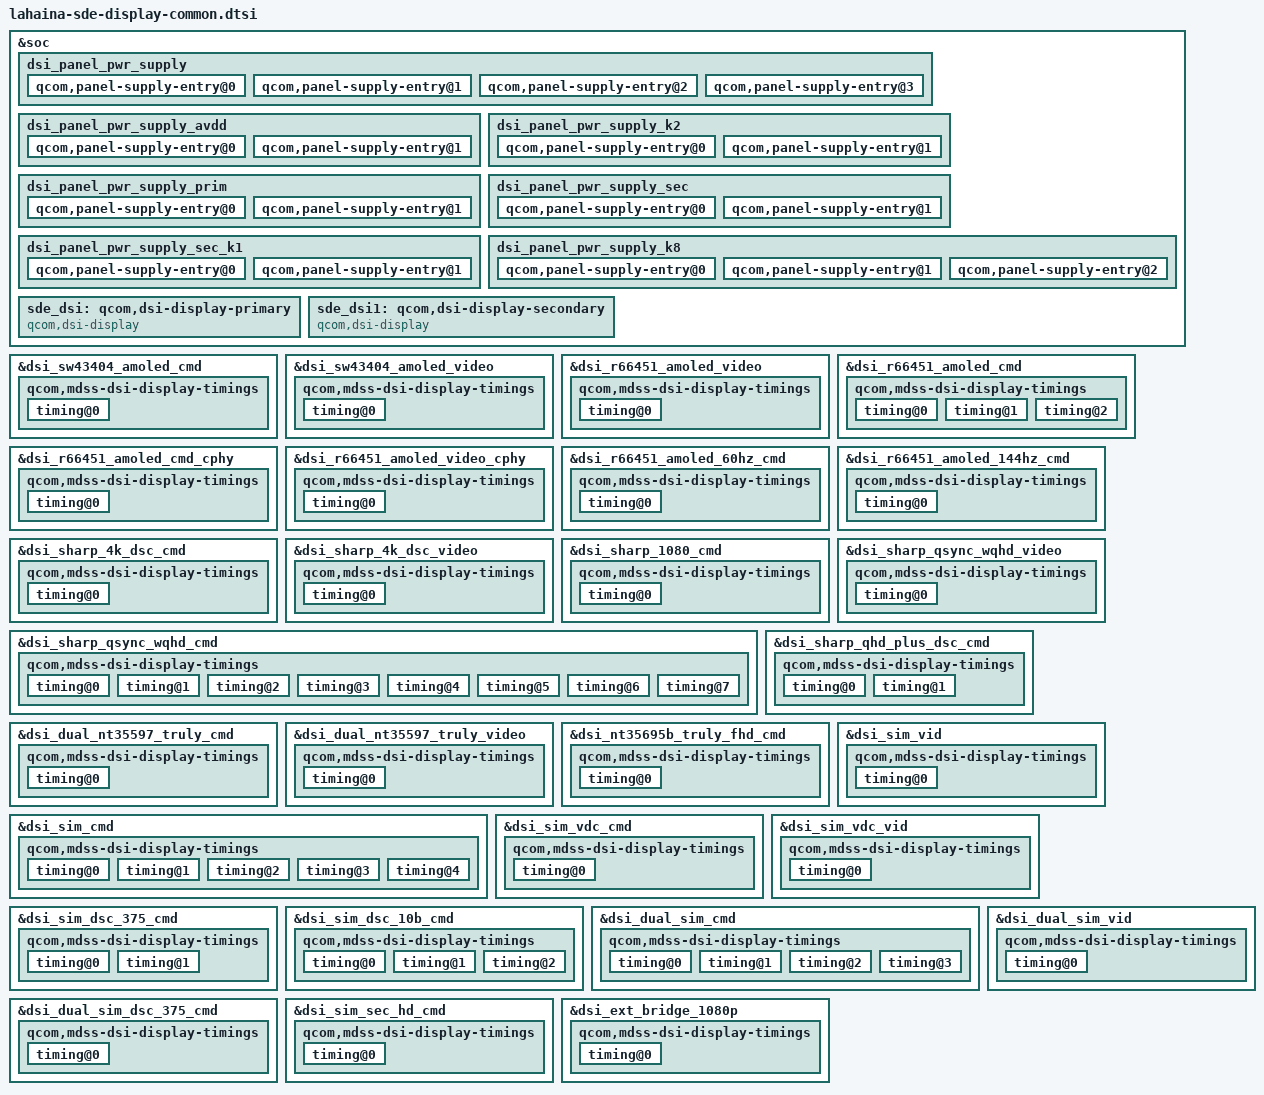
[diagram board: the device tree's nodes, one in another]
#include "dsi-panel-sw43404-amoled-dsc-wqhd-cmd.dtsi"
#include "dsi-panel-sw43404-amoled-dsc-wqhd-video.dtsi"
#include "dsi-panel-sw43404-amoled-dsc-fhd-plus-cmd.dtsi"
#include "dsi-panel-sharp-dsc-4k-cmd.dtsi"
#include "dsi-panel-sharp-dsc-4k-video.dtsi"
#include "dsi-panel-sharp-dsc-qhd-plus-cmd.dtsi"
#include "dsi-panel-sharp-qsync-wqhd-cmd.dtsi"
#include "dsi-panel-sharp-qsync-wqhd-video.dtsi"
#include "dsi-panel-sharp-1080p-cmd.dtsi"
#include "dsi-panel-nt35597-truly-dualmipi-wqxga-cmd.dtsi"
#include "dsi-panel-nt35597-truly-dualmipi-wqxga-video.dtsi"
#include "dsi-panel-nt35695b-truly-fhd-cmd.dtsi"
#include "dsi-panel-nt35695b-truly-fhd-video.dtsi"
#include "dsi-panel-r66451-dsc-fhd-plus-video-cphy.dtsi"
#include "dsi-panel-r66451-dsc-fhd-plus-cmd-cphy.dtsi"
#include "dsi-panel-r66451-dsc-fhd-plus-video.dtsi"
#include "dsi-panel-r66451-dsc-fhd-plus-cmd.dtsi"
#include "dsi-panel-r66451-dsc-fhd-plus-60hz-cmd.dtsi"
#include "dsi-panel-r66451-dsc-fhd-plus-144hz-cmd.dtsi"
#include "dsi-panel-ext-bridge-1080p.dtsi"
#include "dsi-panel-sim-cmd.dtsi"
#include "dsi-panel-sim-video.dtsi"
#include "dsi-panel-sim-dsc375-cmd.dtsi"
#include "dsi-panel-sim-dsc-10bit-cmd.dtsi"
#include "dsi-panel-sim-dualmipi-cmd.dtsi"
#include "dsi-panel-sim-dualmipi-video.dtsi"
#include "dsi-panel-sim-dualmipi-dsc375-cmd.dtsi"
#include "dsi-panel-sim-sec-hd-cmd.dtsi"
#include <dt-bindings/clock/mdss-5nm-pll-clk.h>
#include "dsi-panel-sim-vdc-vid.dtsi"
#include "dsi-panel-sim-vdc-cmd.dtsi"
#include "dsi-panel-k2-38-08-0a-dsc-cmd.dtsi"
#include "dsi-panel-k2-38-08-0a-mp-dsc-cmd.dtsi"
#include "dsi-panel-k2b-38-08-0a-dsc-cmd.dtsi"
#include "dsi-panel-j18-42-06-0a-prim-dsc-cmd.dtsi"
#include "dsi-panel-j18-42-06-0a-sec-dsc-cmd.dtsi"
#include "dsi-panel-k11-38-08-0a-dsc-cmd.dtsi"
#include "dsi-panel-prim-sim-video.dtsi"
#include "dsi-panel-sec-sim-video.dtsi"
#include "dsi-panel-k1-43-06-00-sec-cmd.dtsi"
#include "dsi-panel-k1-43-06-00-sec-video.dtsi"
#include "dsi-panel-k8-42-02-0a-dsc-cmd.dtsi"

&soc {
	dsi_panel_pwr_supply: dsi_panel_pwr_supply {
		#address-cells = <1>;
		#size-cells = <0>;

		qcom,panel-supply-entry@0 {
			reg = <0>;
			qcom,supply-name = "vddio";
			qcom,supply-min-voltage = <1800000>;
			qcom,supply-max-voltage = <1800000>;
			qcom,supply-enable-load = <60700>;
			qcom,supply-disable-load = <80>;
			qcom,supply-post-on-sleep = <20>;
		};

		qcom,panel-supply-entry@1 {
			reg = <1>;
			qcom,supply-name = "vdd";
			qcom,supply-min-voltage = <3000000>;
			qcom,supply-max-voltage = <3000000>;
			qcom,supply-enable-load = <10000>;
			qcom,supply-disable-load = <0>;
			qcom,supply-post-on-sleep = <0>;
		};

		qcom,panel-supply-entry@2 {
			reg = <2>;
			qcom,supply-name = "lab";
			qcom,supply-min-voltage = <4600000>;
			qcom,supply-max-voltage = <6000000>;
			qcom,supply-enable-load = <0>;
			qcom,supply-disable-load = <0>;
		};

		qcom,panel-supply-entry@3 {
			reg = <3>;
			qcom,supply-name = "ibb";
			qcom,supply-min-voltage = <4600000>;
			qcom,supply-max-voltage = <6000000>;
			qcom,supply-enable-load = <0>;
			qcom,supply-disable-load = <0>;
			qcom,supply-post-on-sleep = <20>;
		};
	};

	dsi_panel_pwr_supply_avdd: dsi_panel_pwr_supply_avdd {
		#address-cells = <1>;
		#size-cells = <0>;

		qcom,panel-supply-entry@0 {
			reg = <0>;
			qcom,supply-name = "vddio";
			qcom,supply-min-voltage = <1800000>;
			qcom,supply-max-voltage = <1800000>;
			qcom,supply-enable-load = <182000>;
			qcom,supply-disable-load = <80>;
			qcom,supply-post-on-sleep = <20>;
		};

		qcom,panel-supply-entry@1 {
			reg = <1>;
			qcom,supply-name = "avdd";
			qcom,supply-min-voltage = <4600000>;
			qcom,supply-max-voltage = <6000000>;
			qcom,supply-enable-load = <100000>;
			qcom,supply-disable-load = <100>;
		};
	};

	dsi_panel_pwr_supply_k2: dsi_panel_pwr_supply_k2 {
		#address-cells = <1>;
		#size-cells = <0>;

		qcom,panel-supply-entry@0 {
			reg = <0>;
			qcom,supply-name = "vddio";
			qcom,supply-min-voltage = <1800000>;
			qcom,supply-max-voltage = <1800000>;
			qcom,supply-enable-load = <60700>;
			qcom,supply-disable-load = <80>;
		};

		qcom,panel-supply-entry@1 {
			reg = <1>;
			qcom,supply-name = "vdd";
			qcom,supply-min-voltage = <3000000>;
			qcom,supply-max-voltage = <3000000>;
			qcom,supply-enable-load = <10000>;
			qcom,supply-disable-load = <0>;
			qcom,supply-pre-off-sleep = <10>;
		};
	};

	dsi_panel_pwr_supply_prim: dsi_panel_pwr_supply_prim {
	#address-cells = <1>;
	#size-cells = <0>;

		qcom,panel-supply-entry@0 {
			reg = <0>;
			qcom,supply-name = "vddio";
			qcom,supply-min-voltage = <1900000>;
			qcom,supply-max-voltage = <1900000>;
			qcom,supply-enable-load = <62000>;
			qcom,supply-disable-load = <80>;
			qcom,supply-pre-on-sleep = <0>;
			qcom,supply-pre-off-sleep = <3>;
			qcom,supply-post-on-sleep = <3>;
			qcom,supply-post-off-sleep = <0>;
		};

		qcom,panel-supply-entry@1 {
			reg = <1>;
			qcom,supply-name = "vdd";
			qcom,supply-min-voltage = <3000000>;
			qcom,supply-max-voltage = <3000000>;
			qcom,supply-enable-load = <100000>;
			qcom,supply-disable-load = <100>;
			qcom,supply-pre-on-sleep = <0>;
			qcom,supply-pre-off-sleep = <2>;
			qcom,supply-post-on-sleep = <10>;
			qcom,supply-post-off-sleep = <0>;
		};
	};

	dsi_panel_pwr_supply_sec: dsi_panel_pwr_supply_sec {
	#address-cells = <1>;
	#size-cells = <0>;

		qcom,panel-supply-entry@0 {
			reg = <0>;
			qcom,supply-name = "sec-vddio";
			qcom,supply-min-voltage = <1800000>;
			qcom,supply-max-voltage = <1800000>;
			qcom,supply-enable-load = <62000>;
			qcom,supply-disable-load = <80>;
			qcom,supply-pre-on-sleep = <0>;
			qcom,supply-pre-off-sleep = <2>;
			qcom,supply-post-on-sleep = <3>;
			qcom,supply-post-off-sleep = <0>;
		};

		qcom,panel-supply-entry@1 {
			reg = <1>;
			qcom,supply-name = "sec-vdd";
			qcom,supply-min-voltage = <3000000>;
			qcom,supply-max-voltage = <3000000>;
			qcom,supply-enable-load = <100000>;
			qcom,supply-disable-load = <100>;
			qcom,supply-pre-on-sleep = <0>;
			qcom,supply-pre-off-sleep = <1>;
			qcom,supply-post-on-sleep = <10>;
			qcom,supply-post-off-sleep = <0>;
		};
	};

	dsi_panel_pwr_supply_sec_k1: dsi_panel_pwr_supply_sec_k1 {
	#address-cells = <1>;
	#size-cells = <0>;

		qcom,panel-supply-entry@0 {
			reg = <0>;
			qcom,supply-name = "sec-vddio";
			qcom,supply-min-voltage = <1800000>;
			qcom,supply-max-voltage = <1800000>;
			qcom,supply-enable-load = <62000>;
			qcom,supply-disable-load = <80>;
			qcom,supply-pre-on-sleep = <0>;
			qcom,supply-pre-off-sleep = <2>;
			qcom,supply-post-on-sleep = <3>;
			qcom,supply-post-off-sleep = <0>;
		};

		qcom,panel-supply-entry@1 {
			reg = <1>;
			qcom,supply-name = "sec-vdd";
			qcom,supply-min-voltage = <3000000>;
			qcom,supply-max-voltage = <3000000>;
			qcom,supply-enable-load = <100000>;
			qcom,supply-disable-load = <100>;
			qcom,supply-pre-on-sleep = <0>;
			qcom,supply-pre-off-sleep = <1>;
			qcom,supply-post-on-sleep = <10>;
			qcom,supply-post-off-sleep = <0>;
		};
	};

	dsi_panel_pwr_supply_k8: dsi_panel_pwr_supply_k8 {
		#address-cells = <1>;
		#size-cells = <0>;

		qcom,panel-supply-entry@0 {
			reg = <0>;
			qcom,supply-name = "vddio";
			qcom,supply-min-voltage = <1800000>;
			qcom,supply-max-voltage = <1800000>;
			qcom,supply-enable-load = <60700>;
			qcom,supply-disable-load = <80>;
			qcom,supply-pre-off-sleep = <2>;
			qcom,supply-post-on-sleep = <2>;
		};

		qcom,panel-supply-entry@1 {
			reg = <1>;
			qcom,supply-name = "vddd";
			qcom,supply-min-voltage = <1800000>;
			qcom,supply-max-voltage = <1800000>;
			qcom,supply-enable-load = <60700>;
			qcom,supply-disable-load = <80>;
			qcom,supply-pre-off-sleep = <2>;
			qcom,supply-post-on-sleep = <2>;
		};

		qcom,panel-supply-entry@2 {
			reg = <2>;
			qcom,supply-name = "avdd";
			qcom,supply-min-voltage = <3000000>;
			qcom,supply-max-voltage = <3000000>;
			qcom,supply-enable-load = <10000>;
			qcom,supply-disable-load = <0>;
			qcom,supply-pre-off-sleep = <2>;
			qcom,supply-post-on-sleep = <2>;
		};
	};

	sde_dsi: qcom,dsi-display-primary {
		compatible = "qcom,dsi-display";
		label = "primary";

		qcom,dsi-ctrl = <&mdss_dsi0 &mdss_dsi1>;
		qcom,dsi-phy = <&mdss_dsi_phy0 &mdss_dsi_phy1>;

		qcom,mdp = <&mdss_mdp>;
		qcom,dsi-default-panel = <&dsi_sw43404_amoled_cmd>;
		qcom,demura-panel-id = <0x0 0x0>;
	};

	sde_dsi1: qcom,dsi-display-secondary {
		compatible = "qcom,dsi-display";
		label = "secondary";

		qcom,dsi-ctrl = <&mdss_dsi0 &mdss_dsi1>;
		qcom,dsi-phy = <&mdss_dsi_phy0 &mdss_dsi_phy1>;
		qcom,mdp = <&mdss_mdp>;
		qcom,demura-panel-id = <0x0 0x0>;
	};
};

/* PHY TIMINGS REVISION YC with reduced margins*/
&dsi_sw43404_amoled_cmd {
	qcom,dsi-select-clocks = "mux_byte_clk0", "mux_pixel_clk0";
	qcom,dsi-dyn-clk-enable;
	qcom,dsi-dyn-clk-list = <606979440 604450359 601921278>;

	qcom,mdss-dsi-panel-status-check-mode = "reg_read";
	qcom,mdss-dsi-panel-status-command = [06 01 00 01 00 00 01 0a];
	qcom,mdss-dsi-panel-status-command-state = "dsi_lp_mode";
	qcom,mdss-dsi-panel-status-value = <0x9c>;
	qcom,mdss-dsi-panel-status-read-length = <1>;
	qcom,esd-check-enabled;

	qcom,dsi-panel-gpio-address = <0x0F100000 0x1000>;
	qcom,dsi-panel-gpio-pins = <12 24 82>;
	qcom,dsi-panel-gpio-names = "reg-gpio", "reset-gpio", "platform-te-gpio";

	qcom,mdss-dsi-display-timings {
		timing@0 {
			qcom,mdss-dsi-panel-phy-timings = [00 14 05 05 13 13 05
				05 06 02 04 00 12 0a];
			qcom,display-topology = <2 2 1>;
			qcom,default-topology-index = <0>;

			qcom,panel-roi-alignment = <720 180 180 180 1440 180>;
		};
	};
};

&dsi_sw43404_amoled_video {
	qcom,mdss-dsi-qsync-min-refresh-rate = <55>;
	qcom,dsi-select-clocks = "mux_byte_clk0", "mux_pixel_clk0",
			"src_byte_clk0", "src_pixel_clk0",
			"shadow_byte_clk0", "shadow_pixel_clk0";
	qcom,dsi-dyn-clk-enable;
	qcom,dsi-dyn-clk-list = <534712320 532484352 530256384>;
	qcom,dsi-dyn-clk-type = "constant-fps-adjust-hfp";

	qcom,mdss-dsi-panel-status-check-mode = "reg_read";
	qcom,mdss-dsi-panel-status-command = [06 01 00 01 00 00 01 0a];
	qcom,mdss-dsi-panel-status-command-state = "dsi_lp_mode";
	qcom,mdss-dsi-panel-status-value = <0x9c>;
	qcom,mdss-dsi-panel-status-read-length = <1>;
	qcom,esd-check-enabled;

	qcom,dsi-panel-gpio-address = <0x0F100000 0x1000>;
	qcom,dsi-panel-gpio-pins = <12 24>;
	qcom,dsi-panel-gpio-names = "reg-gpio", "reset-gpio";

	qcom,mdss-dsi-display-timings {
		timing@0 {
			qcom,mdss-dsi-panel-phy-timings = [00 14 05 05 13 1e 05
				05 06 02 04 00 12 0a];
			qcom,display-topology = <2 2 1>;
			qcom,default-topology-index = <0>;
		};
	};
};

&dsi_r66451_amoled_video {
	qcom,dsi-select-clocks = "mux_byte_clk0", "mux_pixel_clk0";
	qcom,dsi-supported-dfps-list = <120 90 60>;
	qcom,mdss-dsi-pan-enable-dynamic-fps;
	qcom,mdss-dsi-min-refresh-rate = <60>;
	qcom,mdss-dsi-max-refresh-rate = <120>;
	qcom,mdss-dsi-pan-fps-update = "dfps_immediate_porch_mode_vfp";

	qcom,dsi-panel-gpio-address = <0x0F100000 0x1000>;
	qcom,dsi-panel-gpio-pins = <12 24>;
	qcom,dsi-panel-gpio-names = "reg-gpio", "reset-gpio";

	qcom,mdss-dsi-display-timings {
		timing@0 {
			qcom,mdss-dsi-panel-phy-timings = [00 1b 08 07 0d 0b 08
				08 05 02 04 00 17 0c];
			qcom,display-topology = <2 2 1>;
			qcom,default-topology-index = <0>;
		};
	};
};

&dsi_r66451_amoled_cmd {
	qcom,dsi-select-clocks = "mux_byte_clk0", "mux_pixel_clk0";
	qcom,dsi-select-sec-clocks = "mux_byte_clk1", "mux_pixel_clk1";

	qcom,dsi-panel-gpio-address = <0x0F100000 0x1000>;
	qcom,dsi-panel-gpio-pins = <12 24 82>;
	qcom,dsi-panel-gpio-names = "reg-gpio", "reset-gpio", "platform-te-gpio";

	qcom,mdss-dsi-panel-status-check-mode = "reg_read";
	qcom,mdss-dsi-panel-status-command = [06 01 00 01 00 00 01 0a];
	qcom,mdss-dsi-panel-status-command-state = "dsi_lp_mode";
	qcom,mdss-dsi-panel-status-value = <0x1c>;
	qcom,mdss-dsi-panel-status-read-length = <1>;
	qcom,esd-check-enabled;

	qcom,mdss-dsi-display-timings {
		timing@0 {
			qcom,mdss-dsi-panel-phy-timings = [00 10 04 04 12 1e 04
				04 03 02 04 00 0e 09];
			qcom,display-topology = <2 2 1>;
			qcom,default-topology-index = <0>;
		};

		timing@1 {
			qcom,mdss-dsi-panel-phy-timings = [00 16 06 05 14 1f 06
				06 06 02 04 00 14 0a];
			qcom,display-topology = <2 2 1>;
			qcom,default-topology-index = <0>;
		};

		timing@2 {
			qcom,mdss-dsi-panel-phy-timings = [00 1c 08 07 17 16 07
				07 08 02 04 00 19 0c];
			qcom,display-topology = <2 2 1>;
			qcom,default-topology-index = <0>;
		};
	};
};

&dsi_r66451_amoled_cmd_cphy {
	qcom,dsi-select-clocks = "mux_byte_clk0", "mux_pixel_clk0",
			"cphy_byte_clk0", "cphy_pixel_clk0";
	qcom,dsi-dyn-clk-enable;
	qcom,dsi-dyn-clk-list = <195173804 194360579 193547355>;
	qcom,mdss-dsi-display-timings {
		timing@0 {
			qcom,mdss-dsi-panel-phy-timings = [00 00 00 00 1e 17 04
				19 03 02 04 00 00 00];
			qcom,display-topology = <2 2 1>;
			qcom,default-topology-index = <0>;
		};
	};
};

&dsi_r66451_amoled_video_cphy {
	qcom,dsi-select-clocks = "mux_byte_clk0", "mux_pixel_clk0",
			"cphy_byte_clk0", "cphy_pixel_clk0",
			"shadow_cphybyte_clk0", "shadow_cphypixel_clk0";
	qcom,dsi-dyn-clk-enable;
	qcom,dsi-dyn-clk-list = <394178400 392535990 387608760>;
	qcom,dsi-dyn-clk-type = "constant-fps-adjust-hfp";
	qcom,mdss-dsi-display-timings {
		timing@0 {
			qcom,mdss-dsi-panel-phy-timings = [00 00 00 00 1e 17 04
				19 03 02 04 00 00 00];
			qcom,display-topology = <2 2 1>;
			qcom,default-topology-index = <0>;
		};
	};
};

&dsi_r66451_amoled_60hz_cmd {
	qcom,dsi-select-clocks = "mux_byte_clk0", "mux_pixel_clk0";

	qcom,dsi-dyn-clk-enable;
	qcom,dsi-dyn-clk-list = <327096544 325733641 324370739>;

	qcom,esd-check-enabled;
	qcom,mdss-dsi-panel-status-check-mode = "reg_read";
	qcom,mdss-dsi-panel-status-command = [06 01 00 01 00 00 01 0a];
	qcom,mdss-dsi-panel-status-command-state = "dsi_lp_mode";
	qcom,mdss-dsi-panel-status-value = <0x1c>;
	qcom,mdss-dsi-panel-status-read-length = <1>;

	qcom,mdss-dsi-display-timings {
		timing@0 {
			qcom,mdss-dsi-panel-phy-timings = [00 10 04 04 1e 1e 04
				04 03 02 04 00 10 14];
			qcom,display-topology = <1 1 1>;
			qcom,default-topology-index = <0>;
		};
	};
};

&dsi_r66451_amoled_144hz_cmd {
	qcom,dsi-select-clocks = "mux_byte_clk0", "mux_pixel_clk0";
	qcom,dsi-select-sec-clocks = "mux_byte_clk1", "mux_pixel_clk1";

	qcom,esd-check-enabled;
	qcom,mdss-dsi-panel-status-check-mode = "reg_read";
	qcom,mdss-dsi-panel-status-command = [06 01 00 01 00 00 01 0a];
	qcom,mdss-dsi-panel-status-command-state = "dsi_lp_mode";
	qcom,mdss-dsi-panel-status-value = <0x1c>;
	qcom,mdss-dsi-panel-status-read-length = <1>;

	qcom,mdss-dsi-display-timings {
		timing@0 {
			qcom,mdss-dsi-panel-phy-timings = [00 22 09 09 19 17 09
				09 09 02 04 00 1d 0e];
			qcom,display-topology = <2 2 1>;
			qcom,default-topology-index = <0>;
		};
	};
};

&dsi_sharp_4k_dsc_cmd {
	qcom,dsi-select-clocks = "mux_byte_clk0", "mux_pixel_clk0";

	qcom,mdss-dsi-panel-status-check-mode = "reg_read";
	qcom,mdss-dsi-panel-status-command = [06 01 00 01 00 00 01 0c];
	qcom,mdss-dsi-panel-status-command-state = "dsi_hs_mode";
	qcom,mdss-dsi-panel-status-value = <0x77>;
	qcom,mdss-dsi-panel-on-check-value = <0x77>;
	qcom,mdss-dsi-panel-status-read-length = <1>;
	qcom,esd-check-enabled;

	qcom,mdss-dsi-display-timings {
		timing@0 {
			qcom,mdss-dsi-panel-phy-timings = [00 13 05 04 13 12 05
				05 06 02 04 00 12 09];
			qcom,display-topology = <2 2 2>;
			qcom,default-topology-index = <0>;
		};
	};
};

&dsi_sharp_4k_dsc_video {
	qcom,dsi-select-clocks = "mux_byte_clk0", "mux_pixel_clk0";
	qcom,dsi-select-clocks = "mux_byte_clk0", "mux_pixel_clk0";

	qcom,mdss-dsi-panel-status-check-mode = "reg_read";
	qcom,mdss-dsi-panel-status-command = [06 01 00 01 00 00 01 0c];
	qcom,mdss-dsi-panel-status-command-state = "dsi_lp_mode";
	qcom,mdss-dsi-panel-status-value = <0x77>;
	qcom,mdss-dsi-panel-on-check-value = <0x77>;
	qcom,mdss-dsi-panel-status-read-length = <1>;
	qcom,esd-check-enabled;

	qcom,mdss-dsi-display-timings {
		timing@0 {
			qcom,mdss-dsi-panel-phy-timings = [00 18 06 06 15 14 06
				06 07 02 04 00 15 0b];
			qcom,display-topology = <2 2 2>;
			qcom,default-topology-index = <0>;
		};
	};
};

&dsi_sharp_1080_cmd {
	qcom,dsi-select-clocks = "mux_byte_clk0", "mux_pixel_clk0";

	qcom,mdss-dsi-panel-status-check-mode = "reg_read";
	qcom,mdss-dsi-panel-status-command = [06 01 00 01 00 00 01 0a];
	qcom,mdss-dsi-panel-status-command-state = "dsi_hs_mode";
	qcom,mdss-dsi-panel-status-value = <0x9c>;
	qcom,mdss-dsi-panel-on-check-value = <0x9c>;
	qcom,mdss-dsi-panel-status-read-length = <1>;
	qcom,esd-check-enabled;

	qcom,mdss-dsi-display-timings {
		timing@0 {
			qcom,mdss-dsi-panel-phy-timings = [00 1e 08 07 18 22 08
				08 08 02 04 00 1a 0c];
			qcom,display-topology = <1 0 1>;
			qcom,default-topology-index = <0>;
			qcom,mdss-dsi-panel-clockrate = <900000000>;
		};
	};
};

&dsi_sharp_qsync_wqhd_cmd {
	qcom,dsi-select-clocks = "mux_byte_clk0", "mux_pixel_clk0";

	qcom,mdss-dsi-panel-status-check-mode = "reg_read";
	qcom,mdss-dsi-panel-status-command = [06 01 00 01 00 00 01 0a];
	qcom,mdss-dsi-panel-status-command-state = "dsi_lp_mode";
	qcom,mdss-dsi-panel-status-value = <0x9c>;
	qcom,mdss-dsi-panel-status-read-length = <1>;
	qcom,esd-check-enabled;

	qcom,mdss-dsi-display-timings {
		timing@0 { /* WQHD 60FPS CMD */
			qcom,mdss-dsi-panel-phy-timings = [00 0b 03 02 10 1c 03
				03 02 02 04 00 0b 07];
			qcom,display-topology = <2 2 2>;
			qcom,default-topology-index = <0>;
		};

		timing@1 { /* WQHD 60FPS VID */
			qcom,mdss-dsi-panel-phy-timings = [00 13 05 04 13 1e 05
				05 06 02 04 00 12 09];
			qcom,display-topology = <2 2 2>;
			qcom,default-topology-index = <0>;
		};

		timing@2 { /* FHD 60FPS CMD */
			qcom,mdss-dsi-panel-phy-timings = [00 0a 01 02 0e 1b 02
				02 01 02 04 00 09 07];
			qcom,display-topology = <2 2 2>;
			qcom,default-topology-index = <0>;
		};

		timing@3 { /* WQHD 90FPS CMD */
			qcom,mdss-dsi-panel-phy-timings = [00 10 03 03 11 1e 04
				04 03 02 04 00 0e 08];
			qcom,display-topology = <2 2 2>;
			qcom,default-topology-index = <0>;
		};

		timing@4 { /* WQHD 120FPS CMD */
			qcom,mdss-dsi-panel-phy-timings = [00 13 05 04 13 12 05
				 05 06 02 04 00 12 09];
			qcom,display-topology = <2 2 2>;
			qcom,default-topology-index = <0>;
		};

		timing@5 { /* WQHD 120FPS VID */
			qcom,mdss-dsi-panel-phy-timings = [00 13 05 04 13 12 05
				 05 06 02 04 00 12 09];
			qcom,display-topology = <2 2 2>;
			qcom,default-topology-index = <0>;
		};

		timing@6 { /* FHD 120FPS CMD */
			qcom,mdss-dsi-panel-phy-timings = [00 0d 03 03 10 10 03
				03 02 02 04 00 0c 08];
			qcom,display-topology = <2 2 2>;
			qcom,default-topology-index = <0>;
		};

		timing@7 { /* FHD 90FPS CMD */
			qcom,mdss-dsi-panel-phy-timings = [00 0b 02 02 0f 1c 03
				02 02 02 04 00 0a 07];
			qcom,display-topology = <2 2 2>;
			qcom,default-topology-index = <0>;
		};
	};
};

&dsi_sharp_qsync_wqhd_video {
	qcom,dsi-select-clocks = "mux_byte_clk0", "mux_pixel_clk0";

	qcom,mdss-dsi-panel-status-check-mode = "reg_read";
	qcom,mdss-dsi-panel-status-command = [06 01 00 01 00 00 01 0a];
	qcom,mdss-dsi-panel-status-command-state = "dsi_lp_mode";
	qcom,mdss-dsi-panel-status-value = <0x9c>;
	qcom,mdss-dsi-panel-status-read-length = <1>;
	qcom,esd-check-enabled;

	qcom,mdss-dsi-display-timings {
		timing@0 {
			qcom,mdss-dsi-panel-phy-timings = [00 13 05 04 13 1e 05
				05 06 02 04 00 12 09];
			qcom,display-topology = <2 2 2>;
			qcom,default-topology-index = <0>;
		};
	};
};

&dsi_sharp_qhd_plus_dsc_cmd {
	qcom,dsi-select-clocks = "mux_byte_clk0", "mux_pixel_clk0";
	qcom,mdss-dsi-display-timings {
		timing@0 { /* 120 FPS */
			qcom,mdss-dsi-panel-phy-timings = [00 16 05 05 14 13 06
				06 06 02 04 00 13 0a];
			qcom,display-topology = <2 2 2>;
			qcom,default-topology-index = <0>;
		};

		timing@1 { /* 60 FPS*/
			qcom,mdss-dsi-panel-phy-timings = [00 1a 07 06 16 15 07
				07 07 02 04 00 17 0b];
			qcom,display-topology = <2 2 2>;
			qcom,default-topology-index = <0>;
		};
	};
};

&dsi_dual_nt35597_truly_cmd {
	qcom,dsi-select-clocks = "mux_byte_clk0", "mux_pixel_clk0";

	qcom,mdss-dsi-panel-status-check-mode = "reg_read";
	qcom,mdss-dsi-panel-status-command = [06 01 00 01 00 00 01 0a];
	qcom,mdss-dsi-panel-status-command-state = "dsi_hs_mode";
	qcom,mdss-dsi-panel-status-value = <0x9c>;
	qcom,mdss-dsi-panel-on-check-value = <0x9c>;
	qcom,mdss-dsi-panel-status-read-length = <1>;
	qcom,esd-check-enabled;

	qcom,mdss-dsi-display-timings {
		timing@0 {
			 /* DPHY regular margins */
			qcom,mdss-dsi-panel-phy-timings = [00 19 06 06 21 20 06
				06 07 02 04 00 17 16 ];
			qcom,display-topology = <2 0 2>,
						<1 0 2>;
			qcom,default-topology-index = <0>;
		};
	};
};

&dsi_dual_nt35597_truly_video {
	qcom,dsi-supported-dfps-list = <60 57 55>;
	qcom,mdss-dsi-pan-enable-dynamic-fps;
	qcom,mdss-dsi-min-refresh-rate = <53>;
	qcom,mdss-dsi-max-refresh-rate = <60>;
	qcom,mdss-dsi-pan-fps-update = "dfps_immediate_porch_mode_vfp";
	qcom,dsi-select-clocks = "mux_byte_clk0", "mux_pixel_clk0";

	qcom,mdss-dsi-panel-status-check-mode = "reg_read";
	qcom,mdss-dsi-panel-status-command = [06 01 00 01 00 00 01 0a];
	qcom,mdss-dsi-panel-status-command-state = "dsi_hs_mode";
	qcom,mdss-dsi-panel-status-value = <0x9c>;
	qcom,mdss-dsi-panel-on-check-value = <0x9c>;
	qcom,mdss-dsi-panel-status-read-length = <1>;
	qcom,esd-check-enabled;

	qcom,mdss-dsi-display-timings {
		timing@0 {
			qcom,mdss-dsi-panel-phy-timings = [00 1c 07 07 17 15 07
				07 08 02 04 00 18 0c];
			qcom,display-topology = <2 0 2>,
						<1 0 2>;
			qcom,default-topology-index = <0>;
		};
	};
};

&dsi_nt35695b_truly_fhd_cmd {
	qcom,dsi-select-clocks = "mux_byte_clk0", "mux_pixel_clk0";
	qcom,dsi-select-sec-clocks = "mux_byte_clk1", "mux_pixel_clk1";

	qcom,mdss-dsi-panel-status-check-mode = "reg_read";
	qcom,mdss-dsi-panel-status-command = [06 01 00 01 00 00 01 0a];
	qcom,mdss-dsi-panel-status-command-state = "dsi_hs_mode";
	qcom,mdss-dsi-panel-status-value = <0x9c>;
	qcom,mdss-dsi-panel-on-check-value = <0x9c>;
	qcom,mdss-dsi-panel-status-read-length = <1>;
	qcom,esd-check-enabled;

	qcom,mdss-dsi-display-timings {
		timing@0 {
			/* DPHY regular margins */
			qcom,mdss-dsi-panel-phy-timings = [00 1b 07 06 22 21 07
				07 07 02 04 00 18 16];
			qcom,display-topology = <1 0 1>;
			qcom,default-topology-index = <0>;
		};
	};
};

&dsi_sim_cmd {
	qcom,dsi-select-clocks = "mux_byte_clk0", "mux_pixel_clk0";
	qcom,poms-align-panel-vsync;
	qcom,mdss-dsi-display-timings {
		timing@0 { /* WQHD 60FPS cmd mode*/
			qcom,mdss-dsi-panel-phy-timings = [00 15 06 05 0a 09 06
				06 04 02 04 00 12 0a];
			qcom,display-topology = <1 1 1>,
						<2 2 1>;
			qcom,default-topology-index = <1>;
		};

		timing@1 { /* WQHD 60FPS vid mode*/
			qcom,mdss-dsi-panel-phy-timings = [00 15 06 05 0a 09 06
				06 04 02 04 00 12 0a];
			qcom,display-topology = <1 1 1>,
						<2 2 1>;
			qcom,default-topology-index = <1>;
		};

		timing@2 { /* WQHD 60FPS cmd mode*/
			qcom,mdss-dsi-panel-phy-timings = [00 15 06 06 0a 09 06
				06 04 02 04 00 12 0b];
			qcom,display-topology = <1 1 1>,
						<2 2 1>;
			qcom,default-topology-index = <1>;
		};

		timing@3 { /* FHD 60FPS cmd mode*/
			qcom,mdss-dsi-panel-phy-timings = [00 1c 08 07 0d 0c 08
				08 05 02 04 00 17 0c];
			qcom,display-topology = <1 1 1>,
						<2 2 1>;
			qcom,default-topology-index = <1>;
		};

		timing@4 { /* HD 60FPS cmd mode*/
			qcom,mdss-dsi-panel-phy-timings = [00 24 0a 09 10 0e 0a
				0a 07 02 04 00 1d 0e];
			qcom,display-topology = <1 1 1>,
						<2 2 1>;
			qcom,default-topology-index = <1>;
		};
	};
};

&dsi_sim_vid {
	qcom,dsi-select-clocks = "mux_byte_clk0", "mux_pixel_clk0";
	qcom,mdss-dsi-display-timings {
		timing@0 {
			qcom,mdss-dsi-panel-phy-timings = [01 05 01 01 03 03 01
				01 01 02 04 00 06 06];
			qcom,display-topology = <1 0 1>,
						<2 0 1>;
			qcom,default-topology-index = <0>;
		};
	};
};

&dsi_sim_vdc_cmd {
	qcom,dsi-select-clocks = "mux_byte_clk0", "mux_pixel_clk0";
	qcom,mdss-dsi-display-timings {
		timing@0 {
			qcom,mdss-dsi-panel-phy-timings = [01 05 01 01 03 03 01
				01 01 02 04 00 06 06];
			qcom,display-topology = <2 1 1>;
			qcom,default-topology-index = <0>;
		};
	};
};

&dsi_sim_vdc_vid {
	qcom,dsi-select-clocks = "mux_byte_clk0", "mux_pixel_clk0";
	qcom,mdss-dsi-display-timings {
		timing@0 {
			qcom,mdss-dsi-panel-phy-timings = [01 05 01 01 03 03 01
				01 01 02 04 00 06 06];
			qcom,display-topology = <2 1 1>;
			qcom,default-topology-index = <0>;
		};
	};
};

&dsi_sim_dsc_375_cmd {
	qcom,dsi-select-clocks = "mux_byte_clk0", "mux_pixel_clk0";
	qcom,mdss-dsi-display-timings {
		timing@0 { /* 1080p */
			qcom,mdss-dsi-panel-phy-timings = [00 00 04 04 08 07 05
				05 03 02 04 00 0e 09];
			qcom,display-topology = <1 1 1>;
			qcom,default-topology-index = <0>;
		};

		timing@1 { /* qhd */
			qcom,mdss-dsi-panel-phy-timings = [00 07 02 02 04 04 02
				02 01 02 04 00 08 07];
			qcom,display-topology = <1 1 1>,
						<2 2 1>, /* dsc merge */
						<2 1 1>; /* 3d mux */
			qcom,default-topology-index = <0>;
		};
	};
};

&dsi_sim_dsc_10b_cmd {
	qcom,dsi-select-clocks = "mux_byte_clk0", "mux_pixel_clk0";
	qcom,mdss-dsi-display-timings {
		timing@0 { /* QHD 60fps */
			qcom,mdss-dsi-panel-phy-timings = [00 1c 08 07 23 22 07
				07 05 02 04 00 18 17];
			qcom,display-topology = <1 1 1>;
			qcom,default-topology-index = <0>;
		};

		timing@1 { /* 1080 60fps */
			qcom,mdss-dsi-panel-phy-timings = [00 1e 08 07 24 22 08
				08 05 02 04 00 19 18];
			qcom,display-topology = <1 1 1>,
						<2 2 1>, /* dsc merge */
						<2 1 1>; /* 3d mux */
			qcom,default-topology-index = <0>;
		};

		timing@2 { /* QHD 90fps */
			qcom,mdss-dsi-panel-phy-timings = [00 1c 08 07 23 22 07
				07 05 02 04 00 18 17];
			qcom,display-topology = <1 1 1>;
			qcom,default-topology-index = <0>;
		};
	};
};

&dsi_dual_sim_cmd {
	qcom,dsi-select-clocks = "mux_byte_clk0", "mux_pixel_clk0";
	qcom,mdss-dsi-display-timings {
		timing@0 { /* 5K 60FPS cmd mode*/
			qcom,mdss-dsi-panel-phy-timings = [00 3d 11 10 1b 17 11
				11 0c 02 04 00 30 15];
			qcom,display-topology = <2 0 2>;
			qcom,default-topology-index = <0>;
		};

		timing@1 { /* FHD 60FPS cmd mode*/
			qcom,mdss-dsi-panel-phy-timings = [00 0d 03 03 06 06 04
				04 02 02 04 00 0c 08];
			qcom,display-topology = <2 0 2>;
			qcom,default-topology-index = <0>;
		};

		timing@2 { /* WQHD 60FPS cmd mode*/
			qcom,mdss-dsi-panel-phy-timings = [00 0a 03 03 05 05 03
				03 01 02 04 00 0a 08];
			qcom,display-topology = <2 0 2>,
						<1 0 2>;
			qcom,default-topology-index = <0>;
		};

		timing@3 { /* 4K 60FPS cmd mode*/
			qcom,mdss-dsi-panel-phy-timings = [00 13 05 05 09 08 05
				05 03 02 04 00 10 0a];
			qcom,display-topology = <2 0 2>;
			qcom,default-topology-index = <0>;
		};
	};
};

&dsi_dual_sim_vid {
	qcom,dsi-select-clocks = "mux_byte_clk0", "mux_pixel_clk0";
	qcom,mdss-dsi-display-timings {
		timing@0 {
			qcom,mdss-dsi-panel-phy-timings = [00 17 07 06 0b 0a 07
				07 07 04 02 00 14 0b];
			qcom,display-topology = <2 0 2>,
						<1 0 2>;
			qcom,default-topology-index = <0>;
		};
	};
};

&dsi_dual_sim_dsc_375_cmd {
	qcom,dsi-select-clocks = "mux_byte_clk0", "mux_pixel_clk0";
	qcom,mdss-dsi-display-timings {
		timing@0 { /* 4k  30 FPS*/
			qcom,mdss-dsi-panel-phy-timings = [00 09 03 03 05 05 03
				03 01 02 04 00 09 08];
			qcom,display-topology = <2 2 2>;
			qcom,default-topology-index = <0>;
		};
	};
};

&dsi_sim_sec_hd_cmd {
	qcom,dsi-select-sec-clocks = "mux_byte_clk1", "mux_pixel_clk1";
	qcom,mdss-dsi-display-timings {
		timing@0 {
			qcom,mdss-dsi-panel-phy-timings = [00 1e 08 07 24 22
				08 08 05 02 04 00 19 17];
			qcom,display-topology = <1 0 1>;
			qcom,default-topology-index = <0>;
		};
	};
};

&dsi_ext_bridge_1080p {
	qcom,dsi-select-clocks = "mux_byte_clk0", "mux_pixel_clk0";
	qcom,mdss-dsi-display-timings {
		timing@0 {
			qcom,mdss-dsi-panel-phy-timings = [00 1e 08 07 18 22 08
				08 08 02 04 00 1a 0c];
			qcom,display-topology = <1 0 1>;
			qcom,default-topology-index = <0>;
		};
	};
};
